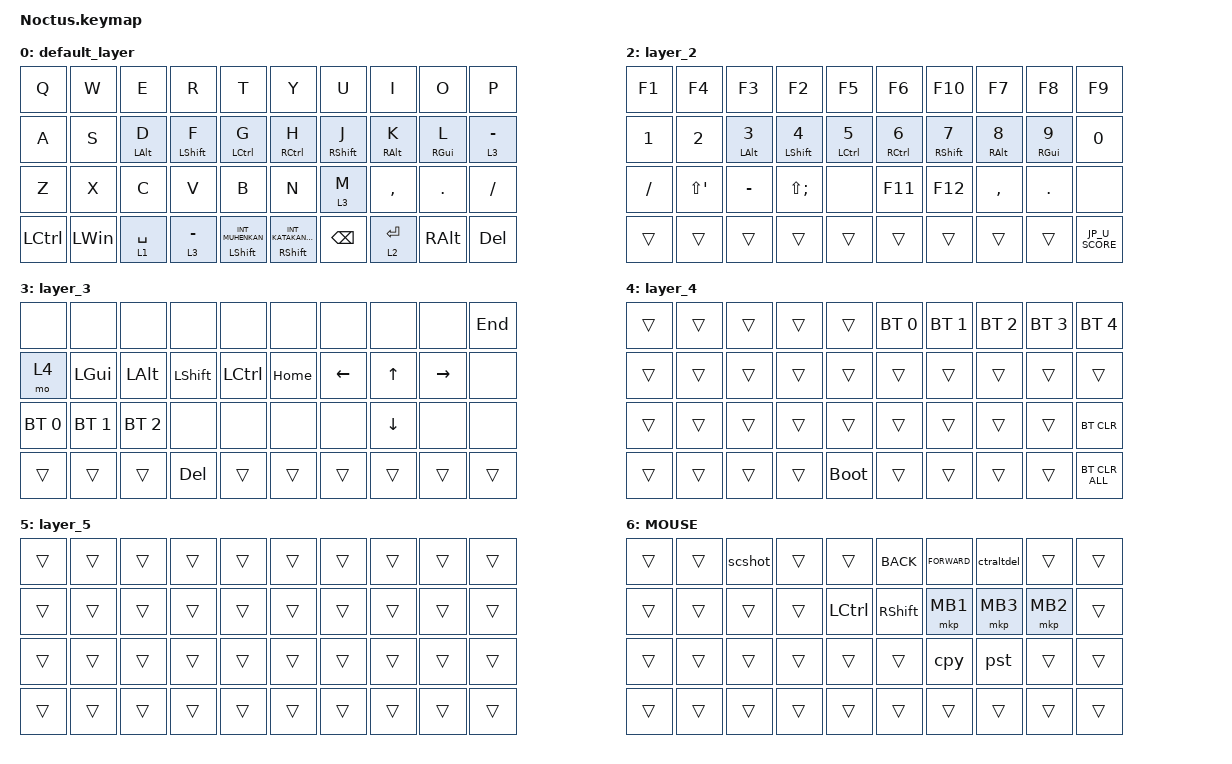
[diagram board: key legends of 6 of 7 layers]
#include <dt-bindings/zmk/input_transform.h>
#include <behaviors.dtsi>
#include <input/processors.dtsi>    // for automouse
#include <dt-bindings/zmk/bt.h>
#include <dt-bindings/zmk/keys.h>
#include <dt-bindings/zmk/pointing.h>

// OS設定を日本語キーボードのまま使用するための変換定義

#define JP_DQUOTE       AT                // "
#define JP_AMPERSAND    CARET             // &
#define JP_QUOTE        AMPERSAND         // '
#define JP_EQUAL        UNDER             // =
#define JP_CARET        EQUAL             // ^
#define JP_YEN          0x89              // ¥
#define JP_PLUS         COLON             // +
#define JP_TILDE        PLUS              // ~
#define JP_PIPE         LS(0x89)          // |
#define JP_AT           LEFT_BRACKET      // @
#define JP_COLON        SINGLE_QUOTE      // :
#define JP_ASTERISK     DOUBLE_QUOTES     // *
#define JP_BACKQUOTE    LEFT_BRACE        // `
#define JP_U_SCORE      LS(0x87)          // _
#define JP_LBRACKET     RIGHT_BRACKET     // [
#define JP_RBRACKET     BACKSLASH         // ]
#define JP_LPAREN       ASTERISK          // (
#define JP_RPAREN       LEFT_PARENTHESIS  // )
#define JP_LBRACE       RIGHT_BRACE       // {
#define JP_RBRACE       PIPE              // }
#define JP_KANA         LANGUAGE_1        // かな
#define JP_EISU         LANGUAGE_2        // 英数
#define JP_HANZEN       GRAVE             // 半角/全角

/{
    macros {
        cpy:cpy {
            compatible = "zmk,behavior-macro";
                #binding-cells = <0>;
                bindings
                    = <&macro_press &kp LCTRL>
                    , <&macro_tap &kp C>
                    , <&macro_release &kp LCTRL>;
        };

        pst:pst {
            compatible = "zmk,behavior-macro";
            #binding-cells = <0>;
            bindings
                = <&macro_press &kp LCTRL>
                , <&macro_tap &kp V>
                , <&macro_release &kp LCTRL>;
        };

        scshot:scshot {
            compatible = "zmk,behavior-macro";
            #binding-cells = <0>;
            bindings
                = <&macro_press &kp LEFT_SHIFT &kp LEFT_GUI>
                , <&macro_tap &kp S>
                , <&macro_release &kp LEFT_SHIFT &kp LEFT_GUI>;
        };

        ctraltdel:ctraltdel {
            compatible = "zmk,behavior-macro";
            #binding-cells = <0>;
            bindings
                = <&macro_press &kp LEFT_CONTROL &kp LEFT_ALT &kp DEL>
                , <&macro_release &kp LEFT_CONTROL &kp LEFT_ALT &kp DEL>;
        };
    };
};

&mt {
    flavor = "balanced";
    quick-tap-ms = <0>;
};

// for extend timer when mouse button
&mkp_input_listener {
    input-processors = <&zip_temp_layer 6 1000>;
};

/ {
    combos {
        compatible = "zmk,combos";

        // toMouseLayer {
        //     bindings = <&mo 6>;
        //     key-positions = <12 13>;
        // };

        Eisu {
            bindings = <&kp INT_MUHENKAN>;
            key-positions = <21 22>;
            layers = <0>;
            timeout-ms = <100>;
        };

        Kana {
            bindings = <&kp INT_KATAKANAHIRAGANA>;
            key-positions = <27 28>;
            layers = <0>;
            timeout-ms = <100>;
        };

        // LeftClick {
        //     bindings = <&mkp LCLK>;
        //     key-positions = <16 17>;
        //     layers = <0>;
        //     require-prior-idle-ms = <150>;
        //     timeout-ms = <100>;
        // };

        // RightClick {
        //     bindings = <&mkp RCLK>;
        //     key-positions = <17 18>;
        //     layers = <0>;
        //     require-prior-idle-ms = <150>;
        //     timeout-ms = <100>;
        // };


        Tab {
            bindings = <&kp TAB>;
            key-positions = <11 12>;
            layers = <0>;
            require-prior-idle-ms = <150>;
            timeout-ms = <80>;
        };

        Capsword {
            bindings = <&caps_word>;
            key-positions = <13 16>;
            layers = <0>;
            require-prior-idle-ms = <150>;
        };

        Escape {
            bindings = <&kp ESC>;
            key-positions = <1 2>;
            layers = <0>;
            require-prior-idle-ms = <150>;
            timeout-ms = <100>;
        };

        DoubleQuote {
            bindings = <&kp LS(NUMBER_2)>;
            key-positions = <7 8>;
            layers = <0>;
            require-prior-idle-ms = <150>;
            timeout-ms = <100>;
        };

        Semicolon {
            bindings = <&kp SEMICOLON>;
            key-positions = <6 7>;
            layers = <0>;
            require-prior-idle-ms = <150>;
            timeout-ms = <100>;
        };

        Colon {
            bindings = <&kp SINGLE_QUOTE>;
            key-positions = <26 27>;
            layers = <0>;
            require-prior-idle-ms = <150>;
            timeout-ms = <100>;
        };

        Scroll {
            bindings = <&mo 3>;
            key-positions = <16 17 18>;
            layers = <0>;
            timeout-ms = <100>;
        };

        Backspace {
            bindings = <&kp BACKSPACE>;
            key-positions = <13 12>;
            layers = <0>;
            timeout-ms = <100>;
        };

        Delete {
            bindings = <&kp DEL>;
            key-positions = <22 23>;
            layers = <0>;
            timeout-ms = <100>;
        };
    };

    // macros {
    //     to_layer_0: to_layer_0 {
    //         compatible = "zmk,behavior-macro-one-param";
    //         #binding-cells = <1>;
    //         bindings = <&to 0 &macro_param_1to1 &kp MACRO_PLACEHOLDER>;
    //         label = "TO_LAYER_0";
    //     };
    // };
    // lt_to_layer_0: lt_to_layer_0 {
    //     compatible = "zmk,behavior-hold-tap";
    //     label = "LAYER_TAP_TO_0";
    //     bindings = <&mo>, <&to_layer_0>;
    //     #binding-cells = <2>;
    //     tapping-term-ms = <200>;
    // };
};

/ {
    behaviors {
        hmr_l: hmr_l {
            compatible = "zmk,behavior-hold-tap";
            bindings = <&kp>, <&kp>;
            #binding-cells = <2>;
            tapping-term-ms = <300>;
            flavor = "balanced";
            hold-trigger-key-positions = <5 6 7 8 9 15 16 17 18 19 25 26 28 27 29 35 36 37>;
            hold-trigger-on-release;
            require-prior-idle-ms = <180>;
        };

        hmr_r: hmr_r {
            compatible = "zmk,behavior-hold-tap";
            bindings = <&kp>, <&kp>;
            #binding-cells = <2>;
            tapping-term-ms = <300>;
            flavor = "balanced";
            hold-trigger-key-positions = <0 1 2 3 4 10 11 12 13 14 20 21 22 23 24 32 33 34>;
            hold-trigger-on-release;
            require-prior-idle-ms = <180>;
        };

        lt_thumb: lt_thumb {
            compatible = "zmk,behavior-hold-tap";
            bindings = <&mo>, <&kp>;
            #binding-cells = <2>;
            tapping-term-ms = <250>;
        };

        lt_arrow: lt_arrow {
            compatible = "zmk,behavior-hold-tap";
            bindings = <&mo>, <&kp>;
            #binding-cells = <2>;
            flavor = "balanced";
            tapping-term-ms = <300>;
            require-prior-idle-ms = <180>;
        };

        lt_scroll: lt_scroll {
            compatible = "zmk,behavior-hold-tap";
            #binding-cells = <2>;
            tapping-term-ms = <300>;
            flavor = "tap-preferred";
            bindings = <&mo>, <&kp>;
            hold-while-undecided;
            require-prior-idle-ms = <150>;
        };

        hmr_l_c: hmr_l_c {
            compatible = "zmk,behavior-hold-tap";
            bindings = <&kp>, <&kp>;
            #binding-cells = <2>;
            tapping-term-ms = <300>;
            flavor = "balanced";
            hold-trigger-key-positions = <5 6 7 8 9 15 16 17 18 19 25 26 28 27 29 35 36 37>;
            hold-trigger-on-release;
            require-prior-idle-ms = <150>;
            hold-while-undecided;
        };

        hmr_r_c: hmr_r_c {
            compatible = "zmk,behavior-hold-tap";
            bindings = <&kp>, <&kp>;
            #binding-cells = <2>;
            tapping-term-ms = <300>;
            flavor = "balanced";
            hold-trigger-key-positions = <0 1 2 3 4 10 11 12 13 14 20 21 22 23 24 32 33 34>;
            hold-trigger-on-release;
            require-prior-idle-ms = <150>;
            hold-while-undecided;
        };

        hmr_num_l: hmr_num_l {
            compatible = "zmk,behavior-hold-tap";
            bindings = <&kp>, <&kp>;
            #binding-cells = <2>;
            tapping-term-ms = <350>;
            flavor = "tap-preferred";
            hold-trigger-key-positions = <5 15 25 32 33 26 28 27 29 19 18 17 16 6 7 8 9>;
            hold-trigger-on-release;
            require-prior-idle-ms = <150>;
            retro-tap;
        };

        hmr_num_r: hmr_num_r {
            compatible = "zmk,behavior-hold-tap";
            bindings = <&kp>, <&kp>;
            #binding-cells = <2>;
            tapping-term-ms = <350>;
            flavor = "tap-preferred";
            hold-trigger-key-positions = <31 30 20 21 22 23 24 14 13 12 11 10 0 1 2 3 4>;
            hold-trigger-on-release;
            require-prior-idle-ms = <150>;
            retro-tap;
        };
    };

    keymap {
        compatible = "zmk,keymap";

        default_layer {
            bindings = <
&kp Q      &kp W         &kp E              &kp R                  &kp T                          &kp Y                                 &kp U                   &kp I               &kp O               &kp P
&kp A      &kp S         &hmr_l LEFT_ALT D  &hmr_l_c LEFT_SHIFT F  &hmr_l_c LCTRL G               &hmr_r_c RCTRL H                      &hmr_r_c RIGHT_SHIFT J  &hmr_r RIGHT_ALT K  &hmr_r RIGHT_GUI L  &lt_arrow 3 MINUS
&kp Z      &kp X         &kp C              &kp V                  &kp B                          &kp N                                 &lt_scroll 3 M          &kp COMMA           &kp DOT             &kp SLASH
&kp LCTRL  &kp LEFT_WIN  &lt_thumb 1 SPACE  &lt 3 MINUS            &mt LEFT_SHIFT INT_MUHENKAN    &mt RIGHT_SHIFT INT_KATAKANAHIRAGANA  &kp BACKSPACE           &lt_thumb 2 ENTER   &kp RIGHT_ALT       &kp DEL
            >;
        };

        layer_1 {
            bindings = <
&none             &none                 &none             &none              &none               &kp EQUAL         &kp LS(LEFT_BRACKET)  &kp RIGHT_BRACKET      &kp BACKSLASH      &kp LEFT_BRACKET
&kp LS(NUMBER_1)  &kp LS(NUMBER_2)      &kp LS(NUMBER_3)  &kp LS(NUMBER_4)   &kp LS(NUMBER_5)    &kp RS(NUMBER_6)  &kp RS(NUMBER_7)      &kp RS(NUMBER_8)       &kp RS(NUMBER_9)   &kp RS(INT1)
&kp SLASH         &kp LS(SINGLE_QUOTE)  &kp MINUS         &kp LS(SEMICOLON)  &none               &kp RS(INT3)      &kp LS(EQUAL)         &kp RS(RIGHT_BRACKET)  &kp RS(BACKSLASH)  &kp INT3
&trans            &trans                &trans            &trans             &trans              &trans            &trans                &trans                 &kp F12
            >;
        };

        layer_2 {
            bindings = <
&kp F1        &kp F4                &kp F3                        &kp F2                          &kp F5                       &kp F6                     &kp F10                          &kp F7                         &kp F8                         &kp F9
&kp NUMBER_1  &kp NUMBER_2          &hmr_num_l LEFT_ALT NUMBER_3  &hmr_num_l LEFT_SHIFT NUMBER_4  &hmr_num_l LCTRL NUMBER_5    &hmr_num_r RCTRL NUMBER_6  &hmr_num_r RIGHT_SHIFT NUMBER_7  &hmr_num_r RIGHT_ALT NUMBER_8  &hmr_num_r RIGHT_GUI NUMBER_9  &kp NUMBER_0
&kp SLASH     &kp LS(SINGLE_QUOTE)  &kp MINUS                     &kp LS(SEMICOLON)               &none                        &kp F11                    &kp F12                          &kp COMMA                      &kp DOT                        &none
&trans        &trans                &trans                        &trans                          &trans                       &trans                     &trans                           &trans                         &trans                         &kp JP_U_SCORE
            >;
        };

        layer_3 {
            bindings = <
&none         &none         &none         &none           &none        &none     &none     &none     &none      &kp END
&mo 4         &kp LEFT_GUI  &kp LEFT_ALT  &kp LEFT_SHIFT  &kp LCTRL    &kp HOME  &kp LEFT  &kp UP    &kp RIGHT  &none
&bt BT_SEL 0  &bt BT_SEL 1  &bt BT_SEL 2  &none           &none        &none     &none     &kp DOWN  &none      &none
&trans        &trans        &trans        &kp DELETE      &trans       &trans    &trans    &trans    &trans     &trans
            >;
        };

        layer_4 {
            bindings = <
&trans  &trans  &trans  &trans  &trans         &bt BT_SEL 0  &bt BT_SEL 1  &bt BT_SEL 2  &bt BT_SEL 3  &bt BT_SEL 4
&trans  &trans  &trans  &trans  &trans         &trans        &trans        &trans        &trans        &trans
&trans  &trans  &trans  &trans  &trans         &trans        &trans        &trans        &trans        &bt BT_CLR
&trans  &trans  &trans  &trans  &bootloader    &trans        &trans        &trans        &trans        &bt BT_CLR_ALL
            >;
        };

        layer_5 {
            bindings = <
&trans  &trans  &trans  &trans  &trans    &trans  &trans  &trans  &trans  &trans
&trans  &trans  &trans  &trans  &trans    &trans  &trans  &trans  &trans  &trans
&trans  &trans  &trans  &trans  &trans    &trans  &trans  &trans  &trans  &trans
&trans  &trans  &trans  &trans  &trans    &trans  &trans  &trans  &trans  &trans
            >;
        };

        MOUSE {
            bindings = <
&trans  &trans  &scshot  &trans  &trans    &kp K_BACK &kp K_FORWARD   &ctraltdel    &trans    &trans
&trans  &trans  &trans  &trans  &kp LEFT_CONTROL    &kp RIGHT_SHIFT  &mkp MB1  &mkp MB3  &mkp MB2  &trans
&trans  &trans  &trans  &trans  &trans    &trans  &cpy    &pst    &trans    &trans
&trans  &trans  &trans  &trans  &trans    &trans  &trans    &trans    &trans    &trans
            >;
        };
    };
};
